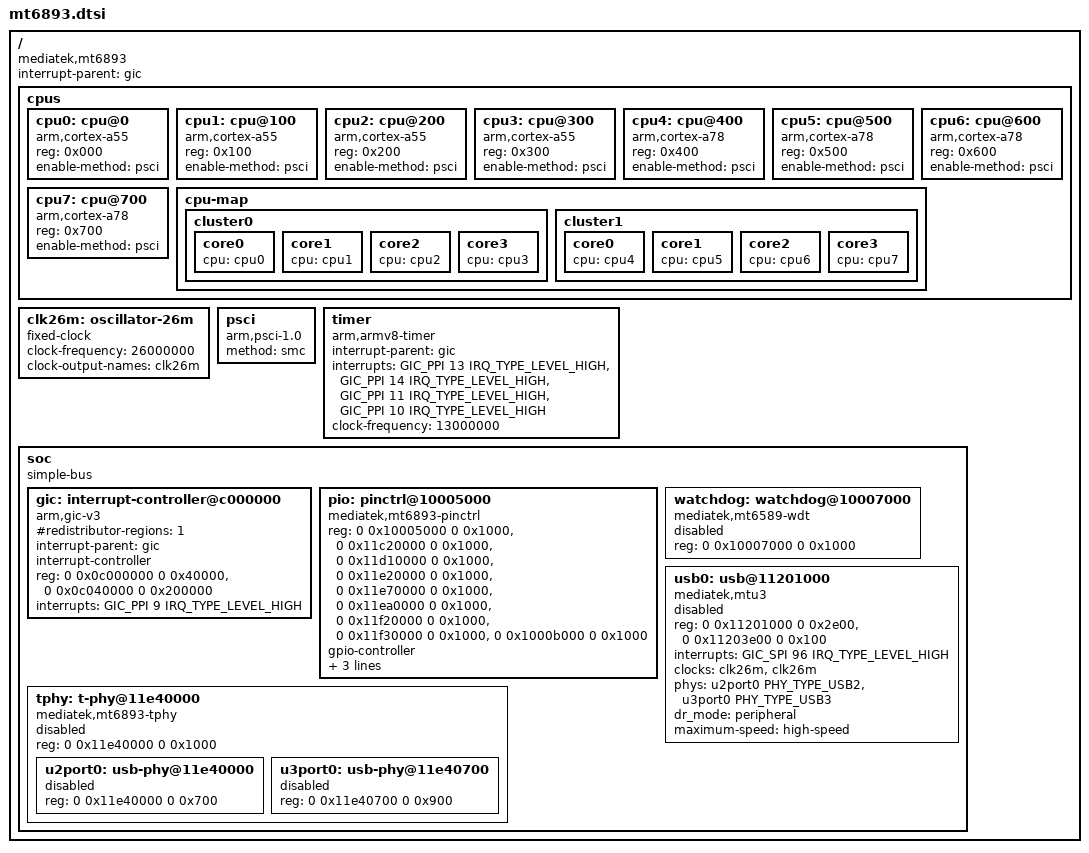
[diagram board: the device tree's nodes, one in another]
// SPDX-License-Identifier: (GPL-2.0 OR BSD-2-Clause)
/*
 * MediaTek MT6893 (Dimensity 1200) SoC
 *
 * Only the blocks that are actually driven by this port are described here.
 * Register bases and interrupt numbers come from the vendor 4.19 tree
 * (arch/arm64/boot/dts/mediatek/mt6893.dts) and are cross-checked against the
 * runtime FDT the stock bootloader hands over.
 */

#include <dt-bindings/interrupt-controller/arm-gic.h>
#include <dt-bindings/interrupt-controller/irq.h>
#include <dt-bindings/phy/phy.h>

/ {
	compatible = "mediatek,mt6893";
	interrupt-parent = <&gic>;
	#address-cells = <2>;
	#size-cells = <2>;

	cpus {
		#address-cells = <1>;
		#size-cells = <0>;

		cpu0: cpu@0 {
			device_type = "cpu";
			compatible = "arm,cortex-a55";
			reg = <0x000>;
			enable-method = "psci";
		};

		cpu1: cpu@100 {
			device_type = "cpu";
			compatible = "arm,cortex-a55";
			reg = <0x100>;
			enable-method = "psci";
		};

		cpu2: cpu@200 {
			device_type = "cpu";
			compatible = "arm,cortex-a55";
			reg = <0x200>;
			enable-method = "psci";
		};

		cpu3: cpu@300 {
			device_type = "cpu";
			compatible = "arm,cortex-a55";
			reg = <0x300>;
			enable-method = "psci";
		};

		cpu4: cpu@400 {
			device_type = "cpu";
			compatible = "arm,cortex-a78";
			reg = <0x400>;
			enable-method = "psci";
		};

		cpu5: cpu@500 {
			device_type = "cpu";
			compatible = "arm,cortex-a78";
			reg = <0x500>;
			enable-method = "psci";
		};

		cpu6: cpu@600 {
			device_type = "cpu";
			compatible = "arm,cortex-a78";
			reg = <0x600>;
			enable-method = "psci";
		};

		cpu7: cpu@700 {
			device_type = "cpu";
			compatible = "arm,cortex-a78";
			reg = <0x700>;
			enable-method = "psci";
		};

		cpu-map {
			cluster0 {
				core0 {
					cpu = <&cpu0>;
				};

				core1 {
					cpu = <&cpu1>;
				};

				core2 {
					cpu = <&cpu2>;
				};

				core3 {
					cpu = <&cpu3>;
				};
			};

			cluster1 {
				core0 {
					cpu = <&cpu4>;
				};

				core1 {
					cpu = <&cpu5>;
				};

				core2 {
					cpu = <&cpu6>;
				};

				core3 {
					cpu = <&cpu7>;
				};
			};
		};
	};

	clk26m: oscillator-26m {
		compatible = "fixed-clock";
		#clock-cells = <0>;
		clock-frequency = <26000000>;
		clock-output-names = "clk26m";
	};

	psci {
		compatible = "arm,psci-1.0";
		method = "smc";
	};

	timer {
		compatible = "arm,armv8-timer";
		interrupt-parent = <&gic>;
		interrupts = <GIC_PPI 13 IRQ_TYPE_LEVEL_HIGH>,
			     <GIC_PPI 14 IRQ_TYPE_LEVEL_HIGH>,
			     <GIC_PPI 11 IRQ_TYPE_LEVEL_HIGH>,
			     <GIC_PPI 10 IRQ_TYPE_LEVEL_HIGH>;
		clock-frequency = <13000000>;
	};

	soc {
		#address-cells = <2>;
		#size-cells = <2>;
		compatible = "simple-bus";
		ranges;

		gic: interrupt-controller@c000000 {
			compatible = "arm,gic-v3";
			#interrupt-cells = <3>;
			#redistributor-regions = <1>;
			interrupt-parent = <&gic>;
			interrupt-controller;
			reg = <0 0x0c000000 0 0x40000>,
			      <0 0x0c040000 0 0x200000>;
			interrupts = <GIC_PPI 9 IRQ_TYPE_LEVEL_HIGH>;
		};

		pio: pinctrl@10005000 {
			compatible = "mediatek,mt6893-pinctrl";
			reg = <0 0x10005000 0 0x1000>,
			      <0 0x11c20000 0 0x1000>,
			      <0 0x11d10000 0 0x1000>,
			      <0 0x11e20000 0 0x1000>,
			      <0 0x11e70000 0 0x1000>,
			      <0 0x11ea0000 0 0x1000>,
			      <0 0x11f20000 0 0x1000>,
			      <0 0x11f30000 0 0x1000>,
			      <0 0x1000b000 0 0x1000>;
			reg-names = "base", "rm", "bm", "lm", "lb", "rt",
				    "lt", "tm", "eint";
			gpio-controller;
			#gpio-cells = <2>;
			gpio-ranges = <&pio 0 0 220>;
			interrupt-controller;
			interrupts = <GIC_SPI 212 IRQ_TYPE_LEVEL_HIGH>;
			#interrupt-cells = <2>;
		};

		watchdog: watchdog@10007000 {
			compatible = "mediatek,mt6589-wdt";
			reg = <0 0x10007000 0 0x1000>;
			#reset-cells = <1>;
			status = "disabled";
		};

		usb0: usb@11201000 {
			compatible = "mediatek,mtu3";
			reg = <0 0x11201000 0 0x2e00>,
			      <0 0x11203e00 0 0x100>;
			reg-names = "mac", "ippc";
			interrupts = <GIC_SPI 96 IRQ_TYPE_LEVEL_HIGH>;
			clocks = <&clk26m>, <&clk26m>;
			clock-names = "sys_ck", "ref_ck";
			phys = <&u2port0 PHY_TYPE_USB2>,
			       <&u3port0 PHY_TYPE_USB3>;
			phy-names = "usb2-phy", "usb3-phy";
			dr_mode = "peripheral";
			maximum-speed = "high-speed";
			status = "disabled";
		};

		tphy: t-phy@11e40000 {
			compatible = "mediatek,mt6893-tphy",
				     "mediatek,generic-tphy-v2";
			reg = <0 0x11e40000 0 0x1000>;
			#address-cells = <2>;
			#size-cells = <2>;
			ranges;
			status = "disabled";

			u2port0: usb-phy@11e40000 {
				reg = <0 0x11e40000 0 0x700>;
				#phy-cells = <1>;
				status = "disabled";
			};

			u3port0: usb-phy@11e40700 {
				reg = <0 0x11e40700 0 0x900>;
				#phy-cells = <1>;
				status = "disabled";
			};
		};
	};
};
